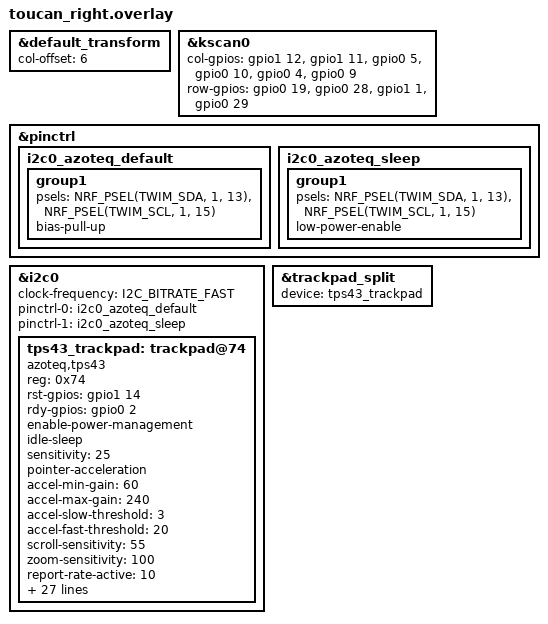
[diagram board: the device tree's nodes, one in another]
#include "toucan.dtsi"
#include <zephyr/dt-bindings/input/input-event-codes.h>

&default_transform {
    col-offset = <6>;
};

&kscan0 {
    col-gpios
    = <&gpio1 12 GPIO_ACTIVE_HIGH>
    , <&gpio1 11 GPIO_ACTIVE_HIGH>
    , <&gpio0 5 GPIO_ACTIVE_HIGH>
    , <&gpio0 10 GPIO_ACTIVE_HIGH>
    , <&gpio0 4 GPIO_ACTIVE_HIGH>
    , <&gpio0 9 GPIO_ACTIVE_HIGH>
    ;

    row-gpios
    = <&gpio0 19 (GPIO_ACTIVE_HIGH | GPIO_PULL_DOWN)>
    , <&gpio0 28 (GPIO_ACTIVE_HIGH | GPIO_PULL_DOWN)>
    , <&gpio1 1 (GPIO_ACTIVE_HIGH | GPIO_PULL_DOWN)>
    , <&gpio0 29 (GPIO_ACTIVE_HIGH | GPIO_PULL_DOWN)>
    ;
};

&pinctrl {
    i2c0_azoteq_default: i2c0_azoteq_default {
        group1 {
            psels = <NRF_PSEL(TWIM_SDA, 1, 13)>,
                    <NRF_PSEL(TWIM_SCL, 1, 15)>;
            bias-pull-up;
        };
    };

    i2c0_azoteq_sleep: i2c0_azoteq_sleep {
        group1 {
            psels = <NRF_PSEL(TWIM_SDA, 1, 13)>,
                    <NRF_PSEL(TWIM_SCL, 1, 15)>;
            low-power-enable;
        };
    };
};

&i2c0 {
   status = "okay";
    clock-frequency = <I2C_BITRATE_FAST>;
    pinctrl-0 = <&i2c0_azoteq_default>;
    pinctrl-1 = <&i2c0_azoteq_sleep>;
    pinctrl-names = "default", "sleep";

    tps43_trackpad: trackpad@74 {
        compatible = "azoteq,tps43";
        reg = <0x74>;
        status = "okay";

        rst-gpios = <&gpio1 14 GPIO_ACTIVE_HIGH>;
        rdy-gpios = <&gpio0 2 GPIO_ACTIVE_HIGH>;

        enable-power-management;
        /* Fully suspend the trackpad (SUSPEND bit: charge transfer halted, ~uA)
           whenever THIS half goes ZMK-idle - 30 s with no right-half key press
           and no trackpad touch (CONFIG_ZMK_IDLE_TIMEOUT). Touching the pad
           counts as activity, so it can never suspend mid-use. A suspended pad
           cannot wake itself (RDY is disabled in suspend): press any right-half
           key and the first touch registers ~300 ms later. Without this
           property the driver only suspends at deep sleep (1 h), leaving the
           pad scanning at ~1.7 mA the whole time. If the wake-up tradeoff ever
           annoys, raise CONFIG_ZMK_IDLE_TIMEOUT rather than removing this. */
        idle-sleep;

        /* Cursor feel: base sensitivity (the driver carries the sub-unit rounding
           remainder so slow/fine moves still register). On top of this, macOS-like
           pointer acceleration scales the gain by finger speed: slow strokes get
           finer control, fast flicks reach across the screen.
           Lowered 50 -> 25 to slow the cursor by 50% (it felt too darty/fast).
           Since gain = sensitivity * accel/100, this scales the whole accel curve
           down uniformly. */
        sensitivity = <25>;
        pointer-acceleration;
        accel-min-gain = <60>;       /* fine control at very low speed */
        accel-max-gain = <240>;      /* fast flick-to-edge */
        accel-slow-threshold = <3>;
        accel-fast-threshold = <20>;

        /* 2-finger scroll. The driver now carries a per-axis sub-detent remainder
           and emits BOTH axes (fluid/diagonal), so a higher sensitivity no longer
           jumps. The listener's zip_scroll_scaler (toucan.dtsi) smooths further. */
        scroll-sensitivity = <55>;
        /* Raised 50 -> 100: at 50 a normal pinch rarely accumulated enough to
           emit even one zoom step, so pinch-to-zoom appeared dead. */
        zoom-sensitivity = <100>;

        /* Fast active report rate (ms) is the biggest single smoothness lever:
           100 Hz while tracking, with a quick idle-touch rate so a resting finger
           stays responsive. Back off (e.g. 13, the firmware default) if logs show
           TPS43_RR_MISSED - or to save power while tracking. */
        report-rate-active = <10>;
        report-rate-idle-touch = <16>;

        /* --- Internal auto power ladder (Active -> Idle-Touch -> Idle -> LP1 ->
           LP2). idle-sleep above covers the "whole half is idle" case; this
           ladder governs trackpad power while the half stays ZMK-ACTIVE (e.g.
           long typing sessions that never touch the pad) and the first 30 s
           after the last touch. Registers are only written when set here;
           unset ones keep firmware defaults (register dump in the driver repo,
           doc/develop.md). NOTE: timeout-lp1 is in 20-SECOND units. */
        report-rate-idle = <50>;   /* full-panel scan 20 Hz (fw default, pinned) */
        report-rate-lp1 = <80>;    /* ALP scan 12.5 Hz (fw default, pinned) */
        report-rate-lp2 = <160>;   /* ALP scan 6.25 Hz floor (fw default, pinned) */
        timeout-active = <5>;      /* fw default, pinned */
        timeout-idle-touch = <20>; /* was 60: a resting finger drops to Idle sooner */
        timeout-idle = <4>;        /* was 10: reach LP1 4 s after finger lift */
        timeout-lp1 = <1>;         /* 1 x 20 s: LP2 floor ~24 s after finger lift */

        /* Optional aggressive tier - trades first-touch latency (up to ~250 ms
           from LP2, comparable to the accepted ~300 ms suspend wake) for a
           lower scanning floor and faster descent:
        report-rate-idle-touch = <32>;
        report-rate-idle = <80>;
        report-rate-lp1 = <120>;
        report-rate-lp2 = <250>;
        timeout-active = <3>;
        timeout-idle-touch = <10>;
        timeout-idle = <2>;
        */

        filter-settings=<0x0B>;

        /* Tap / hold timing for a snappier, more macOS-like click and drag. */
        tap-time = <180>;
        hold-time = <300>;

        /* Pinch-to-zoom: emits one momentary press+release per zoom step.
           zoom-step is the accumulated pinch magnitude needed to fire one step -
           larger = coarser/fewer. Lowered 30 -> 20 (with zoom-sensitivity raised
           to 100) so a normal pinch reliably produces visible zoom steps. The
           driver caps the steps emitted per report, so this can't flood.
           Mapped on the host in config/toucan.keymap (Cmd +/- on macOS). */
        zoom-in-code = <INPUT_BTN_4>;
        zoom-out-code = <INPUT_BTN_5>;
        zoom-step = <20>;

        /* 3-finger swipes: latched + threshold-based, so each swipe fires
           exactly once and uses codes distinct from the 1-finger swipe codes
           (NORTH/SOUTH/EAST/WEST) so the host can tell them apart. Requires the
           `swipes` gesture below. Tune the threshold (raw travel) to taste. */
        three-finger-swipe-up-code = <INPUT_BTN_6>;
        three-finger-swipe-down-code = <INPUT_BTN_7>;
        three-finger-swipe-left-code = <INPUT_BTN_8>;
        three-finger-swipe-right-code = <INPUT_BTN_9>;
        /* Lowered so a normal-length 3-finger swipe fires reliably once. The
           driver now keeps accumulating across a transient 4th-finger brush
           (counts >= 3) instead of resetting, so the latch is more dependable. */
        three-finger-swipe-threshold = <120>;

        scroll;
        two-finger-tap;
        single-tap;
        press-and-hold;
        swipes;
        zoom;

        switch-xy;
        invert-scroll-y;
    };
};

&trackpad_split {
    device = <&tps43_trackpad>;
};
